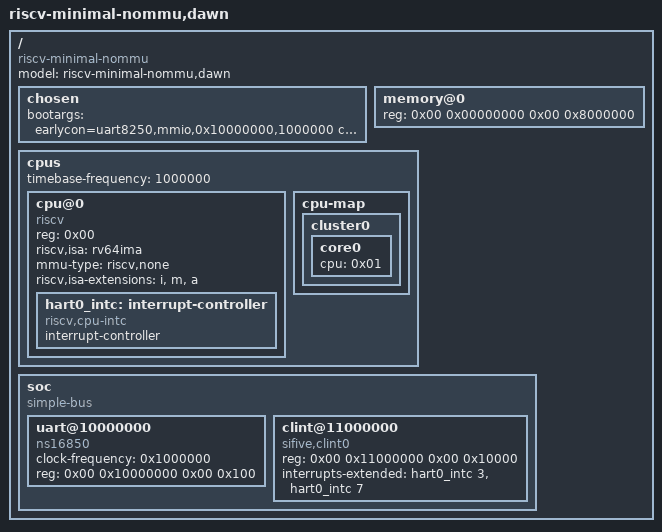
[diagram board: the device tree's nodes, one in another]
/dts-v1/;

/ {
    #address-cells = <0x02>;
    #size-cells = <0x02>;
    compatible = "riscv-minimal-nommu";
    model = "riscv-minimal-nommu,dawn";

    chosen {
        bootargs = "earlycon=uart8250,mmio,0x10000000,1000000 console=ttyS0";
        /* linux,initrd-start = <0x7000000>; */
        /* linux,initrd-end   = <0x8000000>; */
    };

    memory@0 {
        device_type = "memory";
        reg = <0x00 0x00000000 0x00 0x8000000>;
    };

    cpus {
        #address-cells = <0x01>;
        #size-cells = <0x00>;
        timebase-frequency = <1000000>;

        cpu@0 {
            device_type = "cpu";
            reg = <0x00>;
            status = "okay";
            compatible = "riscv";
            riscv,isa = "rv64ima";
            mmu-type = "riscv,none";
            riscv,isa-extensions = "i", "m", "a";

            hart0_intc: interrupt-controller {
                #interrupt-cells = <0x01>;
                interrupt-controller;
                compatible = "riscv,cpu-intc";
            };
        };

        cpu-map {
            cluster0 {
                core0 {
                    cpu = <0x01>;
                };
            };
        };
    };

    soc {
        #address-cells = <0x02>;
        #size-cells = <0x02>;
        compatible = "simple-bus";
        ranges;

        uart@10000000 {
            clock-frequency = <0x1000000>;
            reg = <0x00 0x10000000 0x00 0x100>;
            compatible = "ns16850";
        };

        clint@11000000 {
            reg = <0x00 0x11000000 0x00 0x10000>;
            compatible = "sifive,clint0", "riscv,clint0";
            interrupts-extended = <&hart0_intc 3>, <&hart0_intc 7>;
        };
    };
};
